# AC690N register map
Vendor: JieLi; Series: BR17; File version: 1.0
CPU: PI32 r1, little endian, no MPU, no FPU, 2 interrupt priority bits, 64 interrupts
Registers are 32-bit, read-write, reset 0x0 unless marked. A register's access mark holds for its fields unless they carry their own. Offsets are from the block's base; [hi:lo] are bit positions.

## UART0 — UART interface
Base 0x00060300
Same registers: UART1 0x00060324
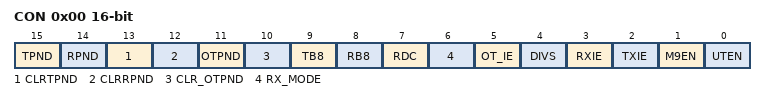
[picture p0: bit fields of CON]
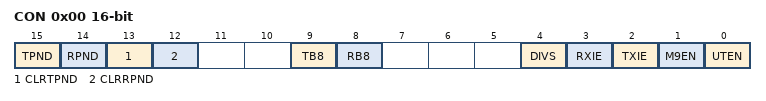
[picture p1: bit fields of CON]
0x00 CON 16-bit — Control register
  [15] TPND ro — TX interrupt pending status
  [14] RPND ro — RX interrupt pending status
  [13] CLRTPND wo — Writing a '1' clears the pending TX interrupt
  [12] CLRRPND wo — Writing a '1' clears the pending RX interrupt
  [11] OTPND ro — Overtime interrupt pending status
  [10] CLR_OTPND wo — Writing a '1' clears the pending overtime interrupt
  [9] TB8 wo — The topmost bit to send in 9-bit mode
  [8] RB8 ro — The topmost received bit in 9-bit mode
  [7] RDC wo — When set to '1', the current received byte amount is written into HRXCNT register (does it exist there?) and then the counter is reset to 0.
  [6] RX_MODE — Reception mode
    0=normal (Reception is done normally); 1=dma (Reception is done through DMA)
  [5] OT_IE — Overtime interrupt enable
  [4] DIVS — Baudrate divider prescaler
    0=div4 (UART clock is divided by 4, e.g. baudrate = uart_clk / 4 / (BAUD + 1)); 1=div3 (UART clock is divided by 3, e.g. (baudrate = uart_clk / 3 / (BAUD + 1))
  [3] RXIE — Reception interrupt enable
  [2] TXIE — Transmission interrupt enable
  [1] M9EN — UART character width
    0=8bit (UART transfers data in 8-bit characters); 1=9bit (UART transfers data in 9-bit characters)
  [0] UTEN — Enable UART
    0=disabled (UART is disabled); 1=enabled (UART is enabled)
0x04 BAUD 16-bit wo — Baudrate divider register
  [15:0] BAUD — Baud rate divider 'baudrate = uart_clk / D / (N + 1)', where D is 3 if DVS=1 and 4 if DVS=0
0x08 BUF 8-bit — Data buffer register
  [7:0] BUF — UART data buffer, writing a byte sends it over, reading returns the last received byte. If the byte was sent, an interrupt is generated. The same for reception, if a byte was received, an interrupt is generated too.
0x0C OTCNT wo — Overtime (timeout) count register
  [31:0] OTCNT — Number of bit clocks (maybe?) in which a falling edge should appear on RX until it times out and triggers the OverTime interrupt.
0x10 TXADR wo — TX DMA base address
  [17:0] TXADR — Base address of the TX DMA buffer. It is 17 bits long, which means that it only covers the low 128k of RAM.
0x14 TXCNT 16-bit wo — TX DMA byte count
  [15:0] TXCNT — Count of bytes to send over via DMA. Writing a value here triggers the TX DMA.
0x18 RXSADR wo — RX DMA start address
  [17:0] RXSADR — Starting address of the RX DMA loop buffer. It is 17 bits long, which means that it only covers the low 128k of RAM.
0x1C RXEADR wo — RX DMA ending address
  [17:0] RXEADR — Ending address of the RX DMA loop buffer. It is 17 bits long, which means that it only covers the low 128k of RAM.
0x20 RXCNT ro — RX DMA byte count
  [31:0] RXCNT — Number of bytes to receive from RX DMA. When this register is written, the interrupt is cleared and DMA will start. After there was enough bytes received, DMA will stop and an interrupt is fired.

## UART2 — UART interface (cut-down variant)
Base 0x00060348
0x00 CON 16-bit — Control register
  [15] TPND ro — TX interrupt pending status
  [14] RPND ro — RX interrupt pending status
  [13] CLRTPND wo — Writing a '1' clears the pending TX interrupt
  [12] CLRRPND wo — Writing a '1' clears the pending RX interrupt
  [9] TB8 wo — The topmost bit to send in 9-bit mode
  [8] RB8 ro — The topmost received bit in 9-bit mode
  [4] DIVS — Baudrate divider prescaler
    0=div4 (UART clock is divided by 4, e.g. baudrate = uart_clk / 4 / (BAUD + 1)); 1=div3 (UART clock is divided by 3, e.g. (baudrate = uart_clk / 3 / (BAUD + 1))
  [3] RXIE — Reception interrupt enable
  [2] TXIE — Transmission interrupt enable
  [1] M9EN — UART character width
    0=8bit (UART transfers data in 8-bit characters); 1=9bit (UART transfers data in 9-bit characters)
  [0] UTEN — Enable UART
    0=disabled (UART is disabled); 1=enabled (UART is enabled)
0x04 BUF 8-bit — Data buffer register
  [7:0] BUF — UART data buffer, writing a byte sends it over, reading returns the last received byte. If the byte was sent, an interrupt is generated. The same for reception, if a byte was received, an interrupt is generated too.
0x08 BAUD 16-bit wo — Baudrate divider register
  [15:0] BAUD — Baud rate divider 'baudrate = uart_clk / D / (N + 1)', where D is 3 if DVS=1 and 4 if DVS=0
